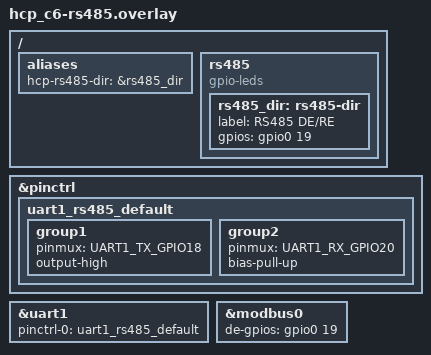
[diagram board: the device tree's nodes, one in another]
/*
 * Copyright (c) 2026 maybetaken
 *
 * ESP32-C6 RS485 variant overlay (mutually exclusive with the default TTL).
 * Applied via: build.sh hcp_c6/... --rs485
 * Re-pins UART1 to the c6-485 physical pads (TX=GPIO18, RX=GPIO20) and adds the
 * DE/RE direction line for the external TTL->RS485 transceiver (DE=GPIO19),
 * exported as alias `hcp-rs485-dir` so the serial backend toggles it.
 *
 * SPDX-License-Identifier: Apache-2.0
 */

#include <zephyr/dt-bindings/gpio/gpio.h>
#include <zephyr/dt-bindings/pinctrl/esp32c6-pinctrl.h>
#include <zephyr/dt-bindings/pinctrl/esp32c6-gpio-sigmap.h>

/ {
	aliases {
		hcp-rs485-dir = &rs485_dir;
	};

	rs485 {
		compatible = "gpio-leds";
		rs485_dir: rs485-dir {
			label = "RS485 DE/RE";
			gpios = <&gpio0 19 GPIO_ACTIVE_HIGH>;
		};
	};
};

&pinctrl {
	uart1_rs485_default: uart1_rs485_default {
		group1 {
			pinmux = <UART1_TX_GPIO18>;
			output-high;
		};
		group2 {
			pinmux = <UART1_RX_GPIO20>;
			bias-pull-up;
		};
	};
};

&uart1 {
	pinctrl-0 = <&uart1_rs485_default>;
};

/* Zephyr's Modbus subsys drives DE itself: idle low, asserted for the duration of
 * each transmission (see modbus_serial.c), which is what the transceiver wants.
 * Same pad as the hcp-rs485-dir alias above, which hcp::serial still uses for the
 * raw loopback self-test - the two are not active in the same build. */
&modbus0 {
	de-gpios = <&gpio0 19 GPIO_ACTIVE_HIGH>;
};
